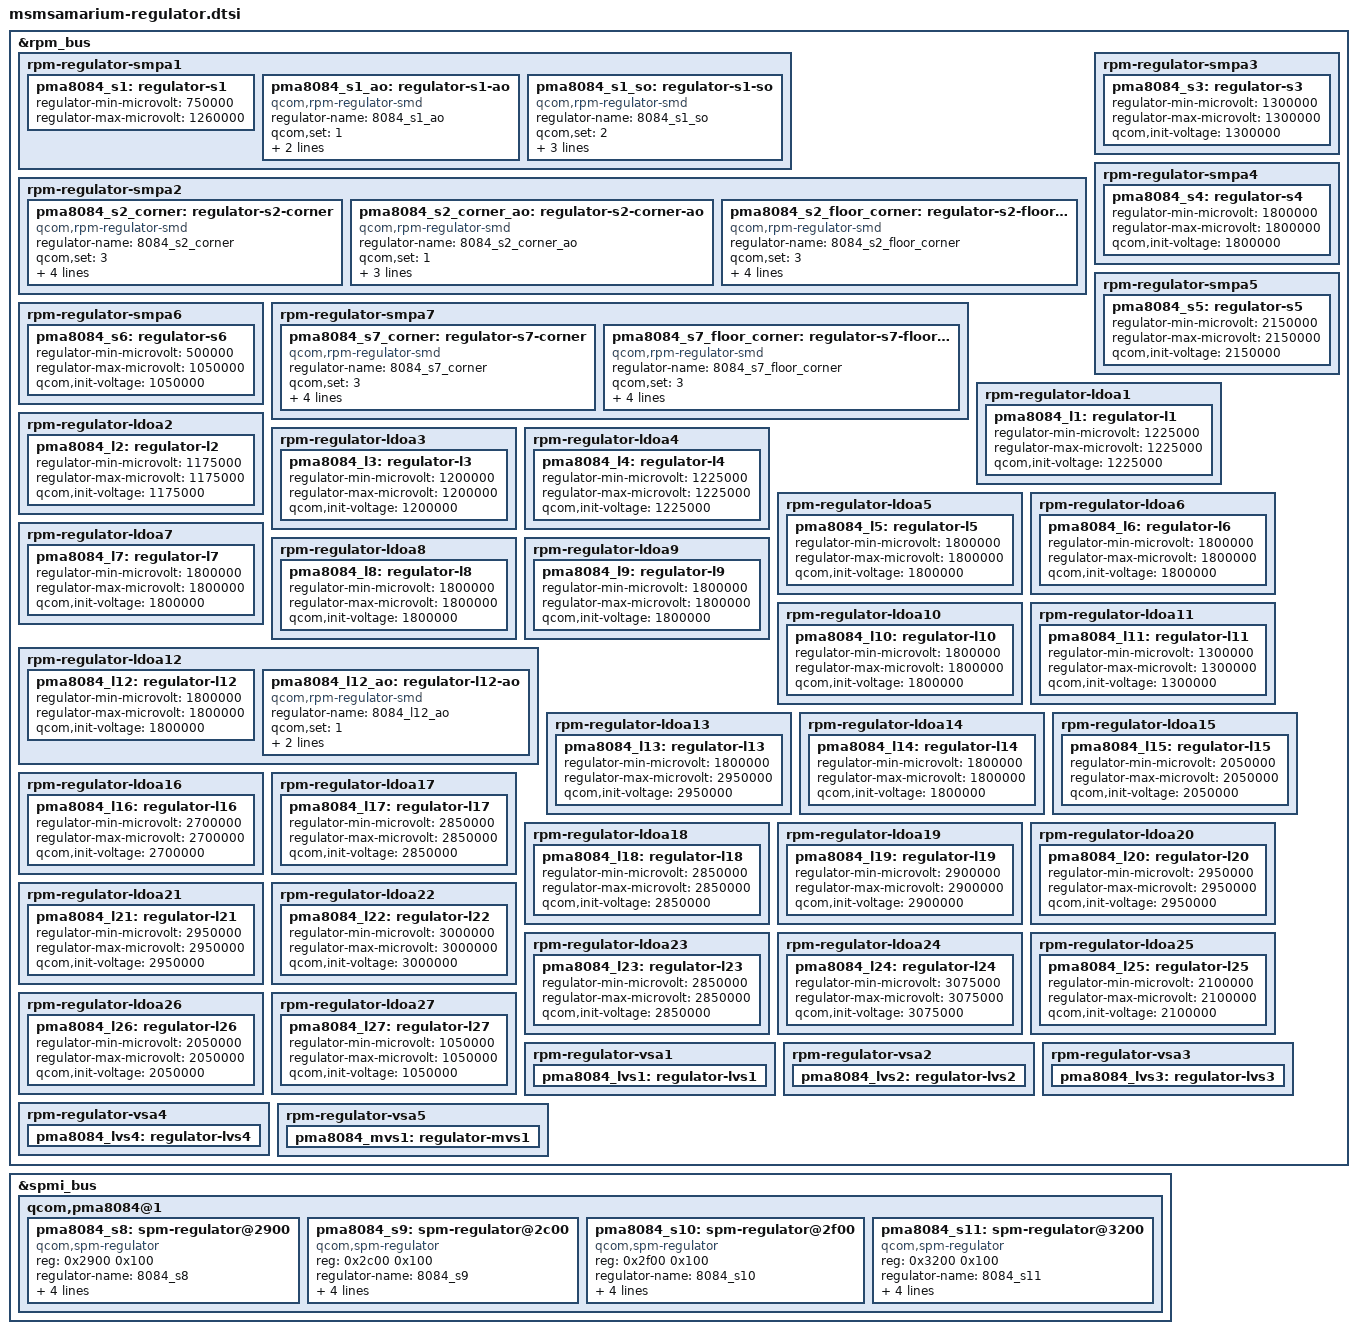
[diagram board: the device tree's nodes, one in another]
/*
 * Copyright (c) 2013, The Linux Foundation. All rights reserved.
 *
 * This program is free software; you can redistribute it and/or modify
 * it under the terms of the GNU General Public License version 2 and
 * only version 2 as published by the Free Software Foundation.
 *
 * This program is distributed in the hope that it will be useful,
 * but WITHOUT ANY WARRANTY; without even the implied warranty of
 * MERCHANTABILITY or FITNESS FOR A PARTICULAR PURPOSE.  See the
 * GNU General Public License for more details.
 */

/* RPM controlled regulators: */
&rpm_bus {
	rpm-regulator-smpa1 {
		status = "okay";
		pma8084_s1: regulator-s1 {
			regulator-min-microvolt = <750000>;
			regulator-max-microvolt = <1260000>;
			status = "okay";
		};
		pma8084_s1_ao: regulator-s1-ao {
			regulator-name = "8084_s1_ao";
			qcom,set = <1>;
			regulator-min-microvolt = <750000>;
			regulator-max-microvolt = <1260000>;
			status = "okay";
			compatible = "qcom,rpm-regulator-smd";
		};
		pma8084_s1_so: regulator-s1-so {
			regulator-name = "8084_s1_so";
			qcom,set = <2>;
			regulator-min-microvolt = <750000>;
			regulator-max-microvolt = <1260000>;
			qcom,init-voltage = <750000>;
			status = "okay";
			compatible = "qcom,rpm-regulator-smd";
		};
	};

	/* PMA8084 S2 + S12 = 2 phase VDD_CX supply */
	rpm-regulator-smpa2 {
		status = "okay";
		pma8084_s2_corner: regulator-s2-corner {
			regulator-name = "8084_s2_corner";
			qcom,set = <3>;
			regulator-min-microvolt = <1>;
			regulator-max-microvolt = <7>;
			qcom,use-voltage-corner;
			compatible = "qcom,rpm-regulator-smd";
			qcom,consumer-supplies = "vdd_dig", "";
		};
		pma8084_s2_corner_ao: regulator-s2-corner-ao {
			regulator-name = "8084_s2_corner_ao";
			qcom,set = <1>;
			regulator-min-microvolt = <1>;
			regulator-max-microvolt = <7>;
			qcom,use-voltage-corner;
			compatible = "qcom,rpm-regulator-smd";
		};
		pma8084_s2_floor_corner: regulator-s2-floor-corner {
			compatible = "qcom,rpm-regulator-smd";
			regulator-name = "8084_s2_floor_corner";
			qcom,set = <3>;
			regulator-min-microvolt = <1>;
			regulator-max-microvolt = <7>;
			qcom,use-voltage-floor-corner;
			qcom,always-send-voltage;
		};
	};

	rpm-regulator-smpa3 {
		status = "okay";
		pma8084_s3: regulator-s3 {
			regulator-min-microvolt = <1300000>;
			regulator-max-microvolt = <1300000>;
			qcom,init-voltage = <1300000>;
			status = "okay";
		};
	};

	rpm-regulator-smpa4 {
		status = "okay";
		pma8084_s4: regulator-s4 {
			regulator-min-microvolt = <1800000>;
			regulator-max-microvolt = <1800000>;
			qcom,init-voltage = <1800000>;
			status = "okay";
		};
	};

	/* Output of PMA8084 S5 and L25 is tied together. */
	rpm-regulator-smpa5 {
		status = "okay";
		pma8084_s5: regulator-s5 {
			regulator-min-microvolt = <2150000>;
			regulator-max-microvolt = <2150000>;
			qcom,init-voltage = <2150000>;
			status = "okay";
		};
	};

	rpm-regulator-smpa6 {
		status = "okay";
		pma8084_s6: regulator-s6 {
			regulator-min-microvolt = <500000>;
			regulator-max-microvolt = <1050000>;
			qcom,init-voltage = <1050000>;
			status = "okay";
		};
	};

	rpm-regulator-smpa7 {
		status = "okay";
		pma8084_s7_corner: regulator-s7-corner {
			compatible = "qcom,rpm-regulator-smd";
			regulator-name = "8084_s7_corner";
			qcom,set = <3>;
			qcom,use-voltage-corner;
			regulator-min-microvolt = <1>;
			regulator-max-microvolt = <7>;
			qcom,init-voltage-corner = <3>; /* SVS SOC */
		};
		pma8084_s7_floor_corner: regulator-s7-floor-corner {
			compatible = "qcom,rpm-regulator-smd";
			regulator-name = "8084_s7_floor_corner";
			qcom,set = <3>;
			regulator-min-microvolt = <1>;
			regulator-max-microvolt = <7>;
			qcom,use-voltage-floor-corner;
			qcom,always-send-voltage;
		};
	};

	rpm-regulator-ldoa1 {
		status = "okay";
		pma8084_l1: regulator-l1 {
			regulator-min-microvolt = <1225000>;
			regulator-max-microvolt = <1225000>;
			qcom,init-voltage = <1225000>;
			status = "okay";
		};
	};

	rpm-regulator-ldoa2 {
		status = "okay";
		pma8084_l2: regulator-l2 {
			regulator-min-microvolt = <1175000>;
			regulator-max-microvolt = <1175000>;
			qcom,init-voltage = <1175000>;
			status = "okay";
		};
	};

	rpm-regulator-ldoa3 {
		status = "okay";
		pma8084_l3: regulator-l3 {
			regulator-min-microvolt = <1200000>;
			regulator-max-microvolt = <1200000>;
			qcom,init-voltage = <1200000>;
			status = "okay";
		};
	};

	rpm-regulator-ldoa4 {
		status = "okay";
		pma8084_l4: regulator-l4 {
			regulator-min-microvolt = <1225000>;
			regulator-max-microvolt = <1225000>;
			qcom,init-voltage = <1225000>;
			status = "okay";
		};
	};

	rpm-regulator-ldoa5 {
		status = "okay";
		pma8084_l5: regulator-l5 {
			regulator-min-microvolt = <1800000>;
			regulator-max-microvolt = <1800000>;
			qcom,init-voltage = <1800000>;
			status = "okay";
		};
	};

	rpm-regulator-ldoa6 {
		status = "okay";
		pma8084_l6: regulator-l6 {
			regulator-min-microvolt = <1800000>;
			regulator-max-microvolt = <1800000>;
			qcom,init-voltage = <1800000>;
			status = "okay";
		};
	};

	rpm-regulator-ldoa7 {
		status = "okay";
		pma8084_l7: regulator-l7 {
			regulator-min-microvolt = <1800000>;
			regulator-max-microvolt = <1800000>;
			qcom,init-voltage = <1800000>;
			status = "okay";
		};
	};

	rpm-regulator-ldoa8 {
		status = "okay";
		pma8084_l8: regulator-l8 {
			regulator-min-microvolt = <1800000>;
			regulator-max-microvolt = <1800000>;
			qcom,init-voltage = <1800000>;
			status = "okay";
		};
	};

	rpm-regulator-ldoa9 {
		status = "okay";
		pma8084_l9: regulator-l9 {
			regulator-min-microvolt = <1800000>;
			regulator-max-microvolt = <1800000>;
			qcom,init-voltage = <1800000>;
			status = "okay";
		};
	};

	rpm-regulator-ldoa10 {
		status = "okay";
		pma8084_l10: regulator-l10 {
			regulator-min-microvolt = <1800000>;
			regulator-max-microvolt = <1800000>;
			qcom,init-voltage = <1800000>;
			status = "okay";
		};
	};

	rpm-regulator-ldoa11 {
		status = "okay";
		pma8084_l11: regulator-l11 {
			regulator-min-microvolt = <1300000>;
			regulator-max-microvolt = <1300000>;
			qcom,init-voltage = <1300000>;
			status = "okay";
		};
	};

	rpm-regulator-ldoa12 {
		status = "okay";
		pma8084_l12: regulator-l12 {
			regulator-min-microvolt = <1800000>;
			regulator-max-microvolt = <1800000>;
			qcom,init-voltage = <1800000>;
			status = "okay";
		};
		pma8084_l12_ao: regulator-l12-ao {
			regulator-name = "8084_l12_ao";
			qcom,set = <1>;
			regulator-min-microvolt = <1800000>;
			regulator-max-microvolt = <1800000>;
			status = "okay";
			compatible = "qcom,rpm-regulator-smd";
		};
	};

	rpm-regulator-ldoa13 {
		status = "okay";
		pma8084_l13: regulator-l13 {
			regulator-min-microvolt = <1800000>;
			regulator-max-microvolt = <2950000>;
			qcom,init-voltage = <2950000>;
			status = "okay";
		};
	};

	rpm-regulator-ldoa14 {
		status = "okay";
		pma8084_l14: regulator-l14 {
			regulator-min-microvolt = <1800000>;
			regulator-max-microvolt = <1800000>;
			qcom,init-voltage = <1800000>;
			status = "okay";
		};
	};

	rpm-regulator-ldoa15 {
		status = "okay";
		pma8084_l15: regulator-l15 {
			regulator-min-microvolt = <2050000>;
			regulator-max-microvolt = <2050000>;
			qcom,init-voltage = <2050000>;
			status = "okay";
		};
	};

	rpm-regulator-ldoa16 {
		status = "okay";
		pma8084_l16: regulator-l16 {
			regulator-min-microvolt = <2700000>;
			regulator-max-microvolt = <2700000>;
			qcom,init-voltage = <2700000>;
			status = "okay";
		};
	};

	rpm-regulator-ldoa17 {
		status = "okay";
		pma8084_l17: regulator-l17 {
			regulator-min-microvolt = <2850000>;
			regulator-max-microvolt = <2850000>;
			qcom,init-voltage = <2850000>;
			status = "okay";
		};
	};

	rpm-regulator-ldoa18 {
		status = "okay";
		pma8084_l18: regulator-l18 {
			regulator-min-microvolt = <2850000>;
			regulator-max-microvolt = <2850000>;
			qcom,init-voltage = <2850000>;
			status = "okay";
		};
	};

	rpm-regulator-ldoa19 {
		status = "okay";
		pma8084_l19: regulator-l19 {
			regulator-min-microvolt = <2900000>;
			regulator-max-microvolt = <2900000>;
			qcom,init-voltage = <2900000>;
			status = "okay";
		};
	};

	rpm-regulator-ldoa20 {
		status = "okay";
		pma8084_l20: regulator-l20 {
			regulator-min-microvolt = <2950000>;
			regulator-max-microvolt = <2950000>;
			qcom,init-voltage = <2950000>;
			status = "okay";
		};
	};

	rpm-regulator-ldoa21 {
		status = "okay";
		pma8084_l21: regulator-l21 {
			regulator-min-microvolt = <2950000>;
			regulator-max-microvolt = <2950000>;
			qcom,init-voltage = <2950000>;
			status = "okay";
		};
	};

	rpm-regulator-ldoa22 {
		status = "okay";
		pma8084_l22: regulator-l22 {
			regulator-min-microvolt = <3000000>;
			regulator-max-microvolt = <3000000>;
			qcom,init-voltage = <3000000>;
			status = "okay";
		};
	};

	rpm-regulator-ldoa23 {
		status = "okay";
		pma8084_l23: regulator-l23 {
			regulator-min-microvolt = <2850000>;
			regulator-max-microvolt = <2850000>;
			qcom,init-voltage = <2850000>;
			status = "okay";
		};
	};

	rpm-regulator-ldoa24 {
		status = "okay";
		pma8084_l24: regulator-l24 {
			regulator-min-microvolt = <3075000>;
			regulator-max-microvolt = <3075000>;
			qcom,init-voltage = <3075000>;
			status = "okay";
		};
	};

	rpm-regulator-ldoa25 {
		status = "okay";
		pma8084_l25: regulator-l25 {
			regulator-min-microvolt = <2100000>;
			regulator-max-microvolt = <2100000>;
			qcom,init-voltage = <2100000>;
			status = "okay";
		};
	};

	rpm-regulator-ldoa26 {
		status = "okay";
		pma8084_l26: regulator-l26 {
			regulator-min-microvolt = <2050000>;
			regulator-max-microvolt = <2050000>;
			qcom,init-voltage = <2050000>;
			status = "okay";
		};
	};

	rpm-regulator-ldoa27 {
		status = "okay";
		pma8084_l27: regulator-l27 {
			regulator-min-microvolt = <1050000>;
			regulator-max-microvolt = <1050000>;
			qcom,init-voltage = <1050000>;
			status = "okay";
		};
	};

	rpm-regulator-vsa1 {
		status = "okay";
		pma8084_lvs1: regulator-lvs1 {
			status = "okay";
		};
	};

	rpm-regulator-vsa2 {
		status = "okay";
		pma8084_lvs2: regulator-lvs2 {
			status = "okay";
		};
	};

	rpm-regulator-vsa3 {
		status = "okay";
		pma8084_lvs3: regulator-lvs3 {
			status = "okay";
		};
	};

	rpm-regulator-vsa4 {
		status = "okay";
		pma8084_lvs4: regulator-lvs4 {
			status = "okay";
		};
	};

	rpm-regulator-vsa5 {
		status = "okay";
		pma8084_mvs1: regulator-mvs1 {
			status = "okay";
		};
	};
};

/* SPM controlled regulators: */
&spmi_bus {
	qcom,pma8084@1 {
		pma8084_s8: spm-regulator@2900 {
			compatible = "qcom,spm-regulator";
			reg = <0x2900 0x100>;
			regulator-name = "8084_s8";
			regulator-min-microvolt = <500000>;
			regulator-max-microvolt = <1250000>;
			qcom,cpu-num = <0>;
			qcom,mode = "pwm";
		};

		pma8084_s9: spm-regulator@2c00 {
			compatible = "qcom,spm-regulator";
			reg = <0x2c00 0x100>;
			regulator-name = "8084_s9";
			regulator-min-microvolt = <500000>;
			regulator-max-microvolt = <1250000>;
			qcom,cpu-num = <1>;
			qcom,mode = "pwm";
		};

		pma8084_s10: spm-regulator@2f00 {
			compatible = "qcom,spm-regulator";
			reg = <0x2f00 0x100>;
			regulator-name = "8084_s10";
			regulator-min-microvolt = <500000>;
			regulator-max-microvolt = <1250000>;
			qcom,cpu-num = <2>;
			qcom,mode = "pwm";
		};

		pma8084_s11: spm-regulator@3200 {
			compatible = "qcom,spm-regulator";
			reg = <0x3200 0x100>;
			regulator-name = "8084_s11";
			regulator-min-microvolt = <500000>;
			regulator-max-microvolt = <1250000>;
			qcom,cpu-num = <3>;
			qcom,mode = "pwm";
		};
	};
};
